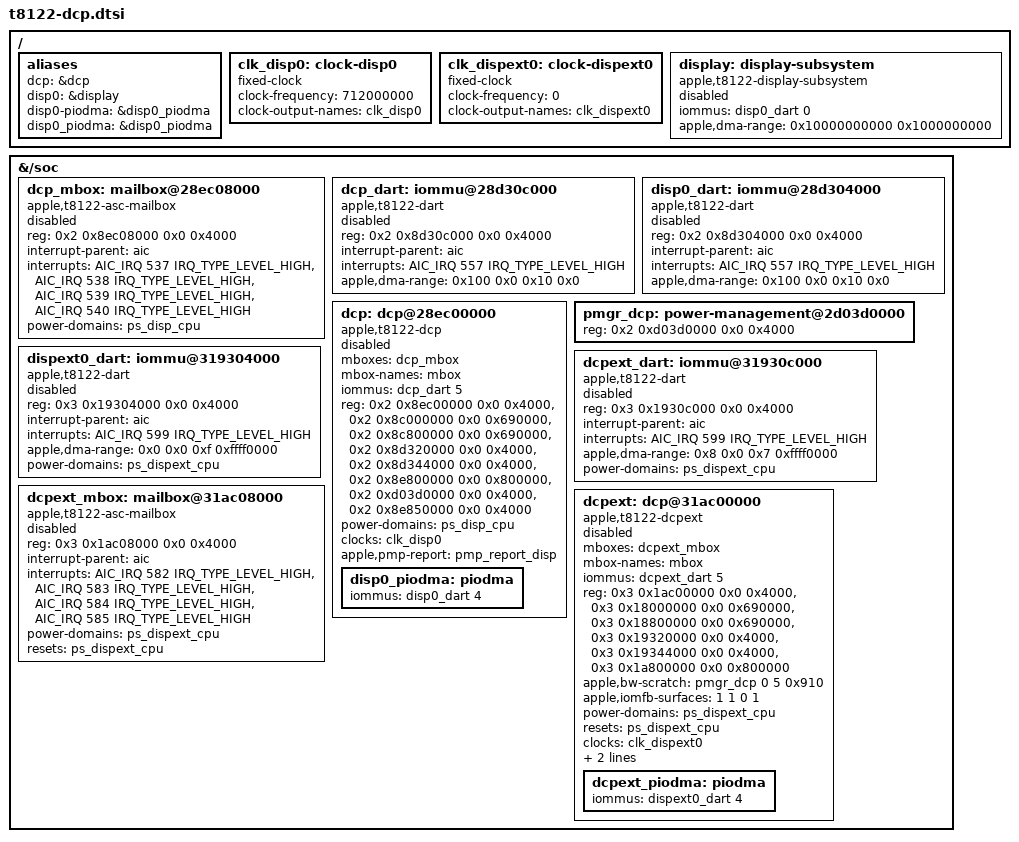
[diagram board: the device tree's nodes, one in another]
// SPDX-License-Identifier: GPL-2.0+ OR MIT
/*
 * T8122 (M3 MacBook Air, J613/J615) internal display and the external display
 * processor (dcpext, at the end of this file).
 *
 * Like T6030, the internal DCP, its mailbox, the two display DARTs and the
 * display subsystem are all described here as status = "disabled". Kernels
 * that cannot take the display over from iBoot keep scanning out through the
 * simple framebuffer, and all of them share one device tree. The boot loader
 * sets apple,t8122-handoff = <1> on the DCP and the display subsystem after
 * it has checked and locked the inherited DART mappings. A kernel display
 * gate that checks this handoff, and can start the PMP that the DCP firmware
 * needs, then enables these nodes. A kernel without such a gate leaves them
 * disabled. The 25G83 profile (t8122-j613-dcp-25g83.dtsi) has its own
 * handoff, which the display driver checks before it enables these nodes.
 *
 * Register, interrupt and DART addresses are SoC addresses from the J613
 * boot device tree: the DCP block and its iop-vbar come from /arm-io/dcp,
 * the six scan-out apertures from /arm-io/disp0, and the two DARTs from
 * /arm-io/dart-dcp and /arm-io/dart-disp0 (one reg window each, as T6030
 * uses). The DCP mailbox interrupts are the four ascwrap IRQs in the
 * send-empty, send-not-empty, recv-empty, recv-not-empty order the SMC
 * mailbox in t8122.dtsi uses. The panel child is board-specific and is added
 * by the board file.
 *
 * The display clock runs at 712 MHz, as iBoot set it up (ADT disp0
 * clock 345 on J613), the same rate as on T6030.
 */

/ {
	aliases {
		dcp = &dcp;
		disp0 = &display;
		disp0-piodma = &disp0_piodma;
		disp0_piodma = &disp0_piodma;
	};

	clk_disp0: clock-disp0 {
		compatible = "fixed-clock";
		#clock-cells = <0>;
		clock-frequency = <712000000>;
		clock-output-names = "clk_disp0";
	};

	/* Rate unknown, as on T8112 and T602x. */
	clk_dispext0: clock-dispext0 {
		compatible = "fixed-clock";
		#clock-cells = <0>;
		clock-frequency = <0>;
		clock-output-names = "clk_dispext0";
	};

	/* Component master without MMIO, outside the simple-bus. */
	display: display-subsystem {
		compatible = "apple,t8122-display-subsystem";
		iommus = <&disp0_dart 0>;
		/* Keep the inherited scanout alias when adding external streams. */
		apple,dma-range = /bits/ 64 <0x10000000000 0x1000000000>;
		status = "disabled";
	};
};

&{/soc} {
	dcp_mbox: mailbox@28ec08000 {
		compatible = "apple,t8122-asc-mailbox", "apple,asc-mailbox-v4";
		reg = <0x2 0x8ec08000 0x0 0x4000>;
		interrupt-parent = <&aic>;
		interrupts = <AIC_IRQ 537 IRQ_TYPE_LEVEL_HIGH>,
			     <AIC_IRQ 538 IRQ_TYPE_LEVEL_HIGH>,
			     <AIC_IRQ 539 IRQ_TYPE_LEVEL_HIGH>,
			     <AIC_IRQ 540 IRQ_TYPE_LEVEL_HIGH>;
		interrupt-names = "send-empty", "send-not-empty",
				  "recv-empty", "recv-not-empty";
		power-domains = <&ps_disp_cpu>;
		#mbox-cells = <0>;
		status = "disabled";
	};

	dcp_dart: iommu@28d30c000 {
		compatible = "apple,t8122-dart", "apple,t8110-dart";
		reg = <0x2 0x8d30c000 0x0 0x4000>;
		interrupt-parent = <&aic>;
		interrupts = <AIC_IRQ 557 IRQ_TYPE_LEVEL_HIGH>;
		#iommu-cells = <1>;
		apple,dma-range = <0x100 0x0 0x10 0x0>;
		status = "disabled";
	};

	disp0_dart: iommu@28d304000 {
		compatible = "apple,t8122-dart", "apple,t8110-dart";
		reg = <0x2 0x8d304000 0x0 0x4000>;
		interrupt-parent = <&aic>;
		interrupts = <AIC_IRQ 557 IRQ_TYPE_LEVEL_HIGH>;
		#iommu-cells = <1>;
		apple,dma-range = <0x100 0x0 0x10 0x0>;
		status = "disabled";
	};

	dcp: dcp@28ec00000 {
		compatible = "apple,t8122-dcp";
		mboxes = <&dcp_mbox>;
		mbox-names = "mbox";
		iommus = <&dcp_dart 5>;
		reg-names = "coproc", "disp-0", "disp-1", "disp-2", "disp-3",
			    "disp-4", "disp-5", "iop-vbar";
		reg = <0x2 0x8ec00000 0x0 0x4000>,
		      <0x2 0x8c000000 0x0 0x690000>,
		      <0x2 0x8c800000 0x0 0x690000>,
		      <0x2 0x8d320000 0x0 0x4000>,
		      <0x2 0x8d344000 0x0 0x4000>,
		      <0x2 0x8e800000 0x0 0x800000>,
		      <0x2 0xd03d0000 0x0 0x4000>,
		      <0x2 0x8e850000 0x0 0x4000>;
		power-domains = <&ps_disp_cpu>;
		clocks = <&clk_disp0>;
		/* The 14.x firmware runs once the PMP acknowledges this request. */
		apple,pmp-report = <&pmp_report_disp>;
		#address-cells = <2>;
		#size-cells = <2>;
		ranges;
		status = "disabled";

		disp0_piodma: piodma {
			iommus = <&disp0_dart 4>;
		};
	};


	/*
	 * The PMGR bandwidth page (ADT disp0/dispext0 reg 5). The internal
	 * DCP lists it as its "disp-5" range; the external one finds it
	 * through apple,bw-scratch, as on T8112 and T602x.
	 */
	pmgr_dcp: power-management@2d03d0000 {
		reg = <0x2 0xd03d0000 0x0 0x4000>;
		reg-names = "dcp-fw-pmgr";
		#apple,bw-scratch-cells = <3>;
	};

	/*
	 * The external display processor (ADT dispext0, dcpext, dart-dispext0
	 * and dart-dcpext). Unlike the internal one it is not handed over by
	 * the boot loader: the boot loader only reserves its firmware and marks
	 * this node apple,t8122-dcpext-firmware-ready, leaving it disabled, and
	 * the driver starts it. The board adds the Type-C routes; the display
	 * gate enables the dcpext, its DARTs, its mailbox and the display
	 * crossbars of those routes together.
	 *
	 * The DMA windows are the ones the working asahi-based kernel uses per
	 * stream: dcpext stream 5 at 0x8_0000_0000 and PIODMA stream 4 from 0
	 * (as on T8112). The display subsystem's stream 0 on dispext0_dart
	 * uses the display subsystem's own high scanout aperture. Its PIODMA
	 * stream keeps the low window below.
	 */
	dispext0_dart: iommu@319304000 {
		compatible = "apple,t8122-dart", "apple,t8110-dart";
		reg = <0x3 0x19304000 0x0 0x4000>;
		interrupt-parent = <&aic>;
		interrupts = <AIC_IRQ 599 IRQ_TYPE_LEVEL_HIGH>;
		#iommu-cells = <1>;
		apple,dma-range = <0x0 0x0 0xf 0xffff0000>;
		power-domains = <&ps_dispext_cpu>;
		status = "disabled";
	};

	dcpext_dart: iommu@31930c000 {
		compatible = "apple,t8122-dart", "apple,t8110-dart";
		reg = <0x3 0x1930c000 0x0 0x4000>;
		interrupt-parent = <&aic>;
		interrupts = <AIC_IRQ 599 IRQ_TYPE_LEVEL_HIGH>;
		#iommu-cells = <1>;
		apple,dma-range = <0x8 0x0 0x7 0xffff0000>;
		power-domains = <&ps_dispext_cpu>;
		status = "disabled";
	};

	dcpext_mbox: mailbox@31ac08000 {
		compatible = "apple,t8122-asc-mailbox", "apple,asc-mailbox-v4";
		reg = <0x3 0x1ac08000 0x0 0x4000>;
		interrupt-parent = <&aic>;
		interrupts = <AIC_IRQ 582 IRQ_TYPE_LEVEL_HIGH>,
			     <AIC_IRQ 583 IRQ_TYPE_LEVEL_HIGH>,
			     <AIC_IRQ 584 IRQ_TYPE_LEVEL_HIGH>,
			     <AIC_IRQ 585 IRQ_TYPE_LEVEL_HIGH>;
		interrupt-names = "send-empty", "send-not-empty",
				  "recv-empty", "recv-not-empty";
		#mbox-cells = <0>;
		power-domains = <&ps_dispext_cpu>;
		resets = <&ps_dispext_cpu>;
		status = "disabled";
	};

	/*
	 * Six ranges as in the ADT dispext0 node: coproc and disp-0 to disp-4,
	 * including the second aperture at 0x318800000. The DCP's map_reg
	 * requests name them by index, so disp-5, the PMGR bandwidth page, is
	 * apple,bw-scratch index 5 (scratch offset 0x910; the internal DCP's is
	 * 0x908).
	 */
	dcpext: dcp@31ac00000 {
		compatible = "apple,t8122-dcpext", "apple,dcpext";
		mboxes = <&dcpext_mbox>;
		mbox-names = "mbox";
		iommus = <&dcpext_dart 5>;
		reg-names = "coproc", "disp-0", "disp-1", "disp-2", "disp-3",
			    "disp-4";
		reg = <0x3 0x1ac00000 0x0 0x4000>,
		      <0x3 0x18000000 0x0 0x690000>,
		      <0x3 0x18800000 0x0 0x690000>,
		      <0x3 0x19320000 0x0 0x4000>,
		      <0x3 0x19344000 0x0 0x4000>,
		      <0x3 0x1a800000 0x0 0x800000>;
		apple,bw-scratch = <&pmgr_dcp 0 5 0x910>;
		apple,iomfb-surfaces = <1 1 0 1>;
		power-domains = <&ps_dispext_cpu>;
		resets = <&ps_dispext_cpu>;
		clocks = <&clk_dispext0>;
		/* Its first mode set completes only with this PMP request. */
		apple,pmp-report = <&pmp_report_dispext>;
		apple,dcp-index = <1>;
		status = "disabled";

		dcpext_piodma: piodma {
			iommus = <&dispext0_dart 4>;
		};
	};
};
